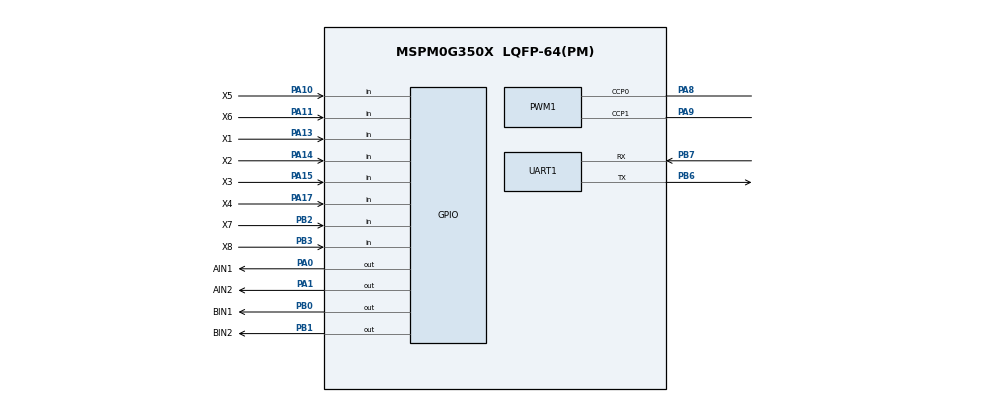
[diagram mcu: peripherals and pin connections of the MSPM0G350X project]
/**
 * @cliArgs --device "MSPM0G350X" --part "Default" --package "LQFP-64(PM)" --product "mspm0_sdk@2.04.00.06"
 * @versions {"tool":"1.23.1+4034"}
 */

/**
 * Import the modules used in this configuration.
 */
const GPIO   = scripting.addModule("/ti/driverlib/GPIO", {}, false);
const GPIO1  = GPIO.addInstance();
const GPIO2  = GPIO.addInstance();
const GPIO3  = GPIO.addInstance();
const GPIO4  = GPIO.addInstance();
const GPIO5  = GPIO.addInstance();
const PWM    = scripting.addModule("/ti/driverlib/PWM", {}, false);
const PWM1   = PWM.addInstance();
const SYSCTL = scripting.addModule("/ti/driverlib/SYSCTL");
const UART   = scripting.addModule("/ti/driverlib/UART", {}, false);
const UART1  = UART.addInstance();

/**
 * Write custom configuration values to the imported modules.
 */
GPIO1.$name                              = "LEDB";
GPIO1.port                               = "PORTB";
GPIO1.associatedPins[0].$name            = "PIN_22";
GPIO1.associatedPins[0].internalResistor = "PULL_DOWN";
GPIO1.associatedPins[0].assignedPin      = "22";

const Board = scripting.addModule("/ti/driverlib/Board", {}, false);

GPIO2.$name                          = "OLED";
GPIO2.associatedPins.create(2);
GPIO2.associatedPins[0].$name        = "OLED_SCL";
GPIO2.associatedPins[0].initialValue = "SET";
GPIO2.associatedPins[0].assignedPort = "PORTB";
GPIO2.associatedPins[0].assignedPin  = "11";
GPIO2.associatedPins[1].$name        = "OLED_SDA";
GPIO2.associatedPins[1].initialValue = "SET";
GPIO2.associatedPins[1].assignedPort = "PORTB";
GPIO2.associatedPins[1].assignedPin  = "10";

GPIO3.$name                          = "AIN";
GPIO3.associatedPins.create(2);
GPIO3.associatedPins[0].$name        = "AIN1";
GPIO3.associatedPins[0].assignedPort = "PORTA";
GPIO3.associatedPins[0].pin.$assign  = "PA0";
GPIO3.associatedPins[1].$name        = "AIN2";
GPIO3.associatedPins[1].pin.$assign  = "PA1";

GPIO4.$name                          = "BIN";
GPIO4.associatedPins.create(2);
GPIO4.associatedPins[0].$name        = "BIN1";
GPIO4.associatedPins[0].assignedPort = "PORTB";
GPIO4.associatedPins[0].pin.$assign  = "PB0";
GPIO4.associatedPins[1].$name        = "BIN2";
GPIO4.associatedPins[1].pin.$assign  = "PB1";

GPIO5.$name                         = "linefollower";
GPIO5.associatedPins.create(8);
GPIO5.associatedPins[0].$name       = "X1";
GPIO5.associatedPins[0].direction   = "INPUT";
GPIO5.associatedPins[0].internalResistor = "PULL_UP";
GPIO5.associatedPins[0].pin.$assign = "PA13";
GPIO5.associatedPins[1].$name       = "X2";
GPIO5.associatedPins[1].direction   = "INPUT";
GPIO5.associatedPins[1].internalResistor = "PULL_UP";
GPIO5.associatedPins[1].pin.$assign = "PA14";
GPIO5.associatedPins[2].$name       = "X3";
GPIO5.associatedPins[2].direction   = "INPUT";
GPIO5.associatedPins[2].internalResistor = "PULL_UP";
GPIO5.associatedPins[2].pin.$assign = "PA15";
GPIO5.associatedPins[3].$name       = "X4";
GPIO5.associatedPins[3].direction   = "INPUT";
GPIO5.associatedPins[3].internalResistor = "PULL_UP";
GPIO5.associatedPins[3].pin.$assign = "PA17";
GPIO5.associatedPins[4].$name       = "X5";
GPIO5.associatedPins[4].direction   = "INPUT";
GPIO5.associatedPins[4].internalResistor = "PULL_UP";
GPIO5.associatedPins[4].pin.$assign = "PA10";
GPIO5.associatedPins[5].$name       = "X6";
GPIO5.associatedPins[5].direction   = "INPUT";
GPIO5.associatedPins[5].internalResistor = "PULL_UP";
GPIO5.associatedPins[5].pin.$assign = "PA11";
GPIO5.associatedPins[6].$name       = "X7";
GPIO5.associatedPins[6].direction   = "INPUT";
GPIO5.associatedPins[6].internalResistor = "PULL_UP";
GPIO5.associatedPins[6].pin.$assign = "PB2";
GPIO5.associatedPins[7].$name       = "X8";
GPIO5.associatedPins[7].direction   = "INPUT";
GPIO5.associatedPins[7].internalResistor = "PULL_UP";
GPIO5.associatedPins[7].pin.$assign = "PB3";

PWM1.$name                      = "PWM_0";
PWM1.timerCount                 = 3200;
PWM1.timerStartTimer            = true;
PWM1.peripheral.ccp0Pin.$assign = "PA8";
PWM1.peripheral.ccp1Pin.$assign = "PA9";
PWM1.PWM_CHANNEL_0.$name        = "ti_driverlib_pwm_PWMTimerCC0";
PWM1.PWM_CHANNEL_1.$name        = "ti_driverlib_pwm_PWMTimerCC1";
PWM1.ccp0PinConfig.$name        = "ti_driverlib_gpio_GPIOPinGeneric0";
PWM1.ccp1PinConfig.$name        = "ti_driverlib_gpio_GPIOPinGeneric1";

SYSCTL.forceDefaultClkConfig = true;

UART1.$name                            = "UART_1";
UART1.targetBaudRate                   = 115200;
UART1.enableFIFO                       = false;
UART1.enabledInterrupts                = ["RX"];
UART1.peripheral.rxPin.$assign         = "PB7";
UART1.peripheral.txPin.$assign         = "PB6";
UART1.txPinConfig.$name                = "ti_driverlib_gpio_GPIOPinGeneric2";
UART1.txPinConfig.direction            = scripting.forceWrite("OUTPUT");
UART1.txPinConfig.hideOutputInversion  = scripting.forceWrite(false);
UART1.txPinConfig.onlyInternalResistor = scripting.forceWrite(false);
UART1.txPinConfig.passedPeripheralType = scripting.forceWrite("Digital");
UART1.rxPinConfig.$name                = "ti_driverlib_gpio_GPIOPinGeneric3";
UART1.rxPinConfig.internalResistor     = "PULL_UP";
UART1.rxPinConfig.hideOutputInversion  = scripting.forceWrite(false);
UART1.rxPinConfig.onlyInternalResistor = scripting.forceWrite(false);
UART1.rxPinConfig.passedPeripheralType = scripting.forceWrite("Digital");

/**
 * Pinmux solution for unlocked pins/peripherals. This ensures that minor changes to the automatic solver in a future
 * version of the tool will not impact the pinmux you originally saw.  These lines can be completely deleted in order to
 * re-solve from scratch.
 */
GPIO1.associatedPins[0].pin.$suggestSolution = "PB22";
Board.peripheral.$suggestSolution            = "DEBUGSS";
Board.peripheral.swclkPin.$suggestSolution   = "PA20";
Board.peripheral.swdioPin.$suggestSolution   = "PA19";
GPIO2.associatedPins[0].pin.$suggestSolution = "PB11";
GPIO2.associatedPins[1].pin.$suggestSolution = "PB10";
PWM1.peripheral.$suggestSolution             = "TIMA0";
SYSCTL.peripheral.$suggestSolution           = "SYSCTL";
UART1.peripheral.$suggestSolution            = "UART1";
